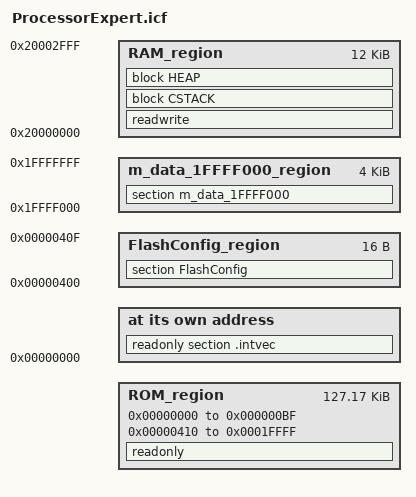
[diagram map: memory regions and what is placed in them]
/* ################################################################### */
/*##
/*##     THIS COMPONENT MODULE IS GENERATED BY THE TOOL. DO NOT MODIFY IT. */
/*##                                   */
/*##     Filename  : ProcessorExpert.icf */
/*##                                   */
/*##     Project   : ProcessorExpert   */
/*##                                   */
/*##     Processor : MKL25Z128VLK4     */
/*##                                   */
/*##     Compiler  : IAR ARM C Compiler */
/*##                                   */
/*##     Date/Time : 2014-05-13, 07:30, # CodeGen: 48 */
/*##                                   */
/*##     Abstract  :                   */
/*##                                   */
/*##     This file is used by the linker. It describes files to be linked, */
/*##     memory ranges, stack size, etc. For detailed description about linker */
/*##     command files see compiler documentation. This file is generated by default. */
/*##     You can switch off generation by setting the property "Generate linker file = no" */
/*##     in the "Build options" tab of the CPU component and then modify this file as needed. */
/*##
/*##                                   */
/*## ###################################################################*/

define symbol m_interrupts_start       = 0x00000000;
define symbol m_interrupts_end         = 0x000000BF;

define symbol m_text_start             = 0x00000410;
define symbol m_text_end               = 0x0001FFFF;

define symbol m_data_1FFFF000_start    = 0x1FFFF000;
define symbol m_data_1FFFF000_end      = 0x1FFFFFFF;

define symbol m_data_start             = 0x20000000;
define symbol m_data_end               = 0x20002FFF;

define symbol FlashConfig_start__    = 0x00000400;
define symbol FlashConfig_end__      = 0x0000040f;

/*-Sizes-*/
define symbol __size_cstack__        = 0x0400;
define symbol __size_heap__          = 0x0800;


define memory mem with size = 4G;

define region ROM_region   = mem:[from m_interrupts_start to m_interrupts_end] | mem:[from m_text_start to m_text_end];

define region RAM_region   = mem:[from m_data_start to m_data_end];

define block CSTACK    with alignment = 8, size = __size_cstack__   { };
define block HEAP      with alignment = 8, size = __size_heap__     { };

define exported symbol __VECTOR_TABLE_START = m_interrupts_start;
define exported symbol __vect_table = m_interrupts_start;

define region FlashConfig_region = mem:[from FlashConfig_start__ to FlashConfig_end__];

define region m_data_1FFFF000_region = mem:[from m_data_1FFFF000_start to m_data_1FFFF000_end];


initialize by copy { readwrite };
do not initialize  { section .noinit };
place at address mem: m_interrupts_start { readonly section .intvec };

place in ROM_region   { readonly };
place in RAM_region   { readwrite,
                        block CSTACK, block HEAP };
place in FlashConfig_region
                      {section FlashConfig};

place in m_data_1FFFF000_region
                      {section m_data_1FFFF000};
